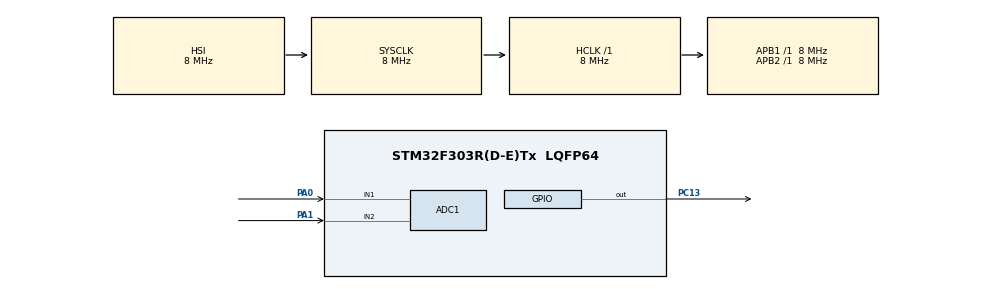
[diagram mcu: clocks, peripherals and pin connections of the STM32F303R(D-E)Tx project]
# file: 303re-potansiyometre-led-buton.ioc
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Mcu.Family=STM32F3
RCC.CortexFreq_Value=8000000
ADC1.Rank-0\#ChannelRegularConversion=1
ADC1.OffsetNumber-0\#ChannelRegularConversion=ADC_OFFSET_NONE
PC13.Signal=GPIO_Output
ProjectManager.StackSize=0x400
PA13.Signal=SYS_JTMS-SWDIO
ADC1.SingleDiff-0\#ChannelRegularConversion=ADC_DIFFERENTIAL_ENDED
ProjectManager.TargetToolchain=STM32CubeIDE
ADC1.SamplingTimeOPAMP-0\#ChannelRegularConversion=ADC_SAMPLETIME_7CYCLES_5
ADC1.Offset-0\#ChannelRegularConversion=0
RCC.USBFreq_Value=16000000
RCC.LSE_VALUE=32768
PA1.Signal=ADC1_IN2
RCC.AHBFreq_Value=8000000
PF0-OSC_IN.Mode=HSE-External-Oscillator
ADC1.Channel-0\#ChannelRegularConversion=ADC_CHANNEL_1
RCC.HSE_VALUE=8000000
board=custom
RCC.APB2Freq_Value=8000000
PA1.Mode=IN1-Differential
PA14.Mode=Serial_Wire
PA0.Mode=IN1-Differential
PA13.Mode=Serial_Wire
Mcu.Name=STM32F303R(D-E)Tx
ADC1.SamplingTime-0\#ChannelRegularConversion=ADC_SAMPLETIME_1CYCLE_5
PA0.Signal=ADC1_IN1
RCC.SYSCLKFreq_VALUE=8000000
Mcu.Package=LQFP64
ADC1.master=1
PA14.Signal=SYS_JTCK-SWCLK
ProjectManager.HeapSize=0x200
RCC.HSI_VALUE=8000000
NVIC.PriorityGroup=NVIC_PRIORITYGROUP_4
ADC1.NbrOfConversionFlag=1
PF0-OSC_IN.Signal=RCC_OSC_IN
PF1-OSC_OUT.Mode=HSE-External-Oscillator
RCC.APB1Freq_Value=8000000
PF1-OSC_OUT.Signal=RCC_OSC_OUT

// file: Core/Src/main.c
 /* USER CODE BEGIN Header */
/**
 ******************************************************************************
 * @file           : main.c
 * @brief          : Main program body
 ******************************************************************************
 * @attention
 *
 * <h2><center>&copy; Copyright (c) 2021 STMicroelectronics.
 * All rights reserved.</center></h2>
 *
 * This software component is licensed by ST under BSD 3-Clause license,
 * the "License"; You may not use this file except in compliance with the
 * License. You may obtain a copy of the License at:
 *                        opensource.org/licenses/BSD-3-Clause
 *
 ******************************************************************************
 */
/* USER CODE END Header */
#include "main.h"

ADC_HandleTypeDef hadc1;

void SystemClock_Config(void);
static void MX_GPIO_Init(void);
static void MX_ADC1_Init(void);

/* USER CODE BEGIN 0 */
int adc;
int i = 1;
/* USER CODE END 0 */

int main(void) {

	/* MCU Configuration--------------------------------------------------------*/

	/* Reset of all peripherals, Initializes the Flash interface and the Systick. */
	HAL_Init();

	/* Configure the system clock */
	SystemClock_Config();

	/* Initialize all configured peripherals */
	MX_GPIO_Init();
	MX_ADC1_Init();

	/* Infinite loop */
	while (1) {

		/* USER CODE BEGIN 3 */
		HAL_ADC_Start(&hadc1);
		if (HAL_ADC_PollForConversion(&hadc1, 1000) == HAL_OK) {

			adc = HAL_ADC_GetValue(&hadc1);

		}

		HAL_GPIO_TogglePin(GPIOC, GPIO_PIN_13);
		HAL_Delay(adc);

	}
	/* USER CODE END 3 */
}

void SystemClock_Config(void) {
	RCC_OscInitTypeDef RCC_OscInitStruct = { 0 };
	RCC_ClkInitTypeDef RCC_ClkInitStruct = { 0 };
	RCC_PeriphCLKInitTypeDef PeriphClkInit = { 0 };

	/** Initializes the RCC Oscillators according to the specified parameters
	 * in the RCC_OscInitTypeDef structure.
	 */
	RCC_OscInitStruct.OscillatorType = RCC_OSCILLATORTYPE_HSI;
	RCC_OscInitStruct.HSIState = RCC_HSI_ON;
	RCC_OscInitStruct.HSICalibrationValue = RCC_HSICALIBRATION_DEFAULT;
	RCC_OscInitStruct.PLL.PLLState = RCC_PLL_ON;
	RCC_OscInitStruct.PLL.PLLSource = RCC_PLLSOURCE_HSI;
	RCC_OscInitStruct.PLL.PLLMUL = RCC_PLL_MUL2;
	RCC_OscInitStruct.PLL.PREDIV = RCC_PREDIV_DIV1;
	if (HAL_RCC_OscConfig(&RCC_OscInitStruct) != HAL_OK) {
		Error_Handler();
	}
	/** Initializes the CPU, AHB and APB buses clocks
	 */
	RCC_ClkInitStruct.ClockType = RCC_CLOCKTYPE_HCLK | RCC_CLOCKTYPE_SYSCLK
			| RCC_CLOCKTYPE_PCLK1 | RCC_CLOCKTYPE_PCLK2;
	RCC_ClkInitStruct.SYSCLKSource = RCC_SYSCLKSOURCE_HSI;
	RCC_ClkInitStruct.AHBCLKDivider = RCC_SYSCLK_DIV1;
	RCC_ClkInitStruct.APB1CLKDivider = RCC_HCLK_DIV1;
	RCC_ClkInitStruct.APB2CLKDivider = RCC_HCLK_DIV1;

	if (HAL_RCC_ClockConfig(&RCC_ClkInitStruct, FLASH_LATENCY_0) != HAL_OK) {
		Error_Handler();
	}
	PeriphClkInit.PeriphClockSelection = RCC_PERIPHCLK_ADC12;
	PeriphClkInit.Adc12ClockSelection = RCC_ADC12PLLCLK_DIV1;
	if (HAL_RCCEx_PeriphCLKConfig(&PeriphClkInit) != HAL_OK) {
		Error_Handler();
	}
}

static void MX_ADC1_Init(void) {

	ADC_MultiModeTypeDef multimode = { 0 };
	ADC_ChannelConfTypeDef sConfig = { 0 };

	/** Common config
	 */
	hadc1.Instance = ADC1;
	hadc1.Init.ClockPrescaler = ADC_CLOCK_ASYNC_DIV1;
	hadc1.Init.Resolution = ADC_RESOLUTION_12B;
	hadc1.Init.ScanConvMode = ADC_SCAN_DISABLE;
	hadc1.Init.ContinuousConvMode = DISABLE;
	hadc1.Init.DiscontinuousConvMode = DISABLE;
	hadc1.Init.ExternalTrigConvEdge = ADC_EXTERNALTRIGCONVEDGE_NONE;
	hadc1.Init.ExternalTrigConv = ADC_SOFTWARE_START;
	hadc1.Init.DataAlign = ADC_DATAALIGN_RIGHT;
	hadc1.Init.NbrOfConversion = 1;
	hadc1.Init.DMAContinuousRequests = DISABLE;
	hadc1.Init.EOCSelection = ADC_EOC_SINGLE_CONV;
	hadc1.Init.LowPowerAutoWait = DISABLE;
	hadc1.Init.Overrun = ADC_OVR_DATA_OVERWRITTEN;
	if (HAL_ADC_Init(&hadc1) != HAL_OK) {
		Error_Handler();
	}
	/** Configure the ADC multi-mode
	 */
	multimode.Mode = ADC_MODE_INDEPENDENT;
	if (HAL_ADCEx_MultiModeConfigChannel(&hadc1, &multimode) != HAL_OK) {
		Error_Handler();
	}
	/** Configure Regular Channel
	 */
	sConfig.Channel = ADC_CHANNEL_1;
	sConfig.Rank = ADC_REGULAR_RANK_1;
	sConfig.SingleDiff = ADC_DIFFERENTIAL_ENDED;
	sConfig.SamplingTime = ADC_SAMPLETIME_1CYCLE_5;
	sConfig.OffsetNumber = ADC_OFFSET_NONE;
	sConfig.Offset = 0;
	if (HAL_ADC_ConfigChannel(&hadc1, &sConfig) != HAL_OK) {
		Error_Handler();
	}

}

static void MX_GPIO_Init(void) {
	GPIO_InitTypeDef GPIO_InitStruct = { 0 };

	/* GPIO Ports Clock Enable */
	__HAL_RCC_GPIOC_CLK_ENABLE();
	__HAL_RCC_GPIOF_CLK_ENABLE();
	__HAL_RCC_GPIOA_CLK_ENABLE();

	/*Configure GPIO pin Output Level */
	HAL_GPIO_WritePin(GPIOC, GPIO_PIN_13, GPIO_PIN_RESET);

	/*Configure GPIO pin : PC13 */
	GPIO_InitStruct.Pin = GPIO_PIN_13;
	GPIO_InitStruct.Mode = GPIO_MODE_OUTPUT_PP;
	GPIO_InitStruct.Pull = GPIO_NOPULL;
	GPIO_InitStruct.Speed = GPIO_SPEED_FREQ_LOW;
	HAL_GPIO_Init(GPIOC, &GPIO_InitStruct);

}

void Error_Handler(void) {
	__disable_irq();
	while (1) {
	}
}

/************************ (C) COPYRIGHT STMicroelectronics *****END OF FILE****/
